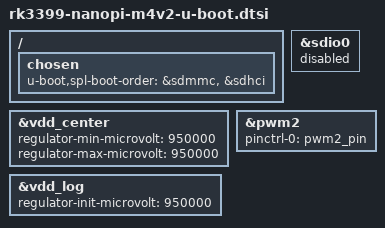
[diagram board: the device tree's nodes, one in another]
// SPDX-License-Identifier: GPL-2.0+
/*
 * Copyright (C) 2019 Jagan Teki <jagan@amarulasolutions.com>
 */

#include "rk3399-nanopi4-u-boot.dtsi"
#include "rk3399-sdram-lpddr4-100.dtsi"

/ {
	chosen {
		u-boot,spl-boot-order = &sdmmc, &sdhci;
	};
};

&sdio0 {
	status = "disabled";
};

&vdd_center {
	regulator-min-microvolt = <950000>;
	regulator-max-microvolt = <950000>;
};

&vdd_log {
	regulator-init-microvolt = <950000>;
};

&pwm2 {
	pinctrl-names = "default";
	pinctrl-0 = <&pwm2_pin>;
};
